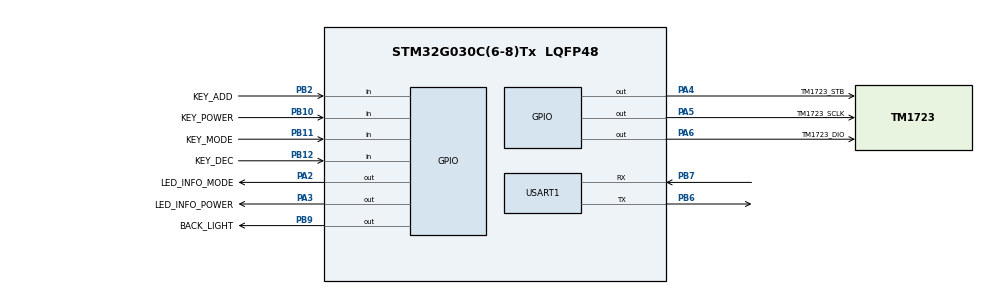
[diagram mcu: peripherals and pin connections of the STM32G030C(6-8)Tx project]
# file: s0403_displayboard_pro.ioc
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Dma.Request0=USART1_RX
Dma.Request1=USART1_TX
Dma.USART1_RX.0.Direction=DMA_PERIPH_TO_MEMORY
Dma.USART1_RX.0.EventEnable=DISABLE
Dma.USART1_RX.0.Instance=DMA1_Channel1
Dma.USART1_RX.0.MemDataAlignment=DMA_MDATAALIGN_BYTE
Dma.USART1_RX.0.MemInc=DMA_MINC_ENABLE
Dma.USART1_RX.0.Mode=DMA_NORMAL
Dma.USART1_RX.0.PeriphDataAlignment=DMA_PDATAALIGN_BYTE
Dma.USART1_RX.0.PeriphInc=DMA_PINC_DISABLE
Dma.USART1_RX.0.Polarity=HAL_DMAMUX_REQ_GEN_RISING
Dma.USART1_RX.0.Priority=DMA_PRIORITY_LOW
Dma.USART1_RX.0.RequestNumber=1
Dma.USART1_RX.0.SignalID=NONE
Dma.USART1_RX.0.SyncEnable=DISABLE
Dma.USART1_RX.0.SyncPolarity=HAL_DMAMUX_SYNC_NO_EVENT
Dma.USART1_RX.0.SyncRequestNumber=1
Dma.USART1_RX.0.SyncSignalID=NONE
Dma.USART1_TX.1.Direction=DMA_MEMORY_TO_PERIPH
Dma.USART1_TX.1.EventEnable=DISABLE
Dma.USART1_TX.1.Instance=DMA1_Channel2
Dma.USART1_TX.1.MemDataAlignment=DMA_MDATAALIGN_BYTE
Dma.USART1_TX.1.MemInc=DMA_MINC_ENABLE
Dma.USART1_TX.1.Mode=DMA_NORMAL
Dma.USART1_TX.1.PeriphDataAlignment=DMA_PDATAALIGN_BYTE
Dma.USART1_TX.1.PeriphInc=DMA_PINC_DISABLE
Dma.USART1_TX.1.Polarity=HAL_DMAMUX_REQ_GEN_RISING
Dma.USART1_TX.1.Priority=DMA_PRIORITY_LOW
Dma.USART1_TX.1.RequestNumber=1
Dma.USART1_TX.1.SignalID=NONE
Dma.USART1_TX.1.SyncEnable=DISABLE
Dma.USART1_TX.1.SyncPolarity=HAL_DMAMUX_SYNC_NO_EVENT
Dma.USART1_TX.1.SyncRequestNumber=1
Dma.USART1_TX.1.SyncSignalID=NONE
Mcu.Family=STM32G0
Mcu.Name=STM32G030C(6-8)Tx
Mcu.Package=LQFP48
NVIC.DMA1_Channel1_IRQn=true\:0\:0\:false\:false\:true\:false\:false\:true\:true
NVIC.DMA1_Channel2_3_IRQn=true\:0\:0\:false\:false\:true\:false\:false\:true\:true
NVIC.TIM16_IRQn=true\:0\:0\:false\:false\:true\:false\:true\:true\:true
NVIC.TIM17_IRQn=true\:3\:0\:false\:false\:true\:false\:false\:true\:true
NVIC.TimeBase=TIM17_IRQn
NVIC.TimeBaseIP=TIM17
NVIC.USART1_IRQn=true\:0\:0\:false\:false\:true\:false\:true\:true\:true
PA13.Mode=Serial_Wire
PA13.Signal=SYS_SWDIO
PA14-BOOT0.Mode=Serial_Wire
PA14-BOOT0.Signal=SYS_SWCLK
PA2.GPIO_Label=LED_INFO_MODE
PA2.Signal=GPIO_Output
PA3.GPIO_Label=LED_INFO_POWER
PA3.Signal=GPIO_Output
PA4.GPIO_Label=TM1723_STB
PA4.Signal=GPIO_Output
PA5.GPIO_Label=TM1723_SCLK
PA5.Signal=GPIO_Output
PA6.GPIO_Label=TM1723_DIO
PA6.Signal=GPIO_Output
PB10.GPIO_Label=KEY_POWER
PB10.Signal=GPIO_Input
PB11.GPIO_Label=KEY_MODE
PB11.Signal=GPIO_Input
PB12.GPIO_Label=KEY_DEC
PB12.Signal=GPIO_Input
PB2.GPIO_Label=KEY_ADD
PB2.Signal=GPIO_Input
PB6.Mode=Asynchronous
PB6.Signal=USART1_TX
PB7.Mode=Asynchronous
PB7.Signal=USART1_RX
PB9.GPIO_Label=BACK_LIGHT
PB9.Signal=GPIO_Output
ProjectManager.HeapSize=0x200
ProjectManager.StackSize=0x400
ProjectManager.TargetToolchain=MDK-ARM V5.32
RCC.ADCFreq_Value=64000000
RCC.AHBFreq_Value=64000000
RCC.CortexFreq_Value=64000000
RCC.EXTERNAL_CLOCK_VALUE=12288000
RCC.HCLKFreq_Value=64000000
RCC.HSE_VALUE=8000000
RCC.HSI_VALUE=16000000
RCC.LSE_VALUE=32768
RCC.SYSCLKFreq_VALUE=64000000
RCC.SYSCLKSource=RCC_SYSCLKSOURCE_PLLCLK
RCC.VCOOutputFreq_Value=128000000
STMicroelectronics.X-CUBE-AZRTOS-G0.1.1.0.ThreadXCcRTOSJjThreadXJjCore=true
STMicroelectronics.X-CUBE-AZRTOS-G0.1.1.0_IsAnAzureRtosMw=true
USART1.VirtualMode-Asynchronous=VM_ASYNC
VP_STMicroelectronics.X-CUBE-AZRTOS-G0_VS_RTOSJjThreadX_6.1.10_1.1.0.Mode=RTOSJjThreadX
VP_SYS_VS_tim17.Mode=TIM17
VP_TIM16_VS_ClockSourceINT.Mode=Enable_Timer
board=custom

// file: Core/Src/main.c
/* USER CODE BEGIN Header */
/**
  ******************************************************************************
  * @file           : main.c
  * @brief          : Main program body
  ******************************************************************************
  * @attention
  *
  * version : 2.4 . be used to LL lib .
  *           data:2025.09.22
  *
  * data:2026.02.27
  * modify 0x6C order send to mainboard sync times is local don't beijing time.
  * data:2026-06-05 be used responsed speed .
  *
  *
  ******************************************************************************
  */
/* USER CODE END Header */
#include "app_threadx.h"
#include "main.h"
#include "dma.h"
#include "tim.h"
#include "usart.h"
#include "gpio.h"

/* USER CODE BEGIN Includes */
#include "bsp.h"
/* USER CODE END Includes */

void SystemClock_Config(void);

int main(void)
{

  /* MCU Configuration--------------------------------------------------------*/

  /* Reset of all peripherals, Initializes the Flash interface and the Systick. */
  HAL_Init();

  /* Configure the system clock */
  SystemClock_Config();

  /* Initialize all configured peripherals */
  MX_GPIO_Init();
  MX_DMA_Init();
  MX_USART1_UART_Init();
  MX_TIM16_Init();
  /* USER CODE BEGIN 2 */
  bsp_init();

  /* USER CODE END 2 */

  MX_ThreadX_Init();

  /* We should never get here as control is now taken by the scheduler */

  /* Infinite loop */
  while (1)
  {

  }
}

void SystemClock_Config(void)
{
  LL_FLASH_SetLatency(LL_FLASH_LATENCY_2);
  while(LL_FLASH_GetLatency() != LL_FLASH_LATENCY_2)
  {
  }

  /* HSI configuration and activation */
  LL_RCC_HSI_Enable();
  while(LL_RCC_HSI_IsReady() != 1)
  {
  }

  /* Main PLL configuration and activation */
  LL_RCC_PLL_ConfigDomain_SYS(LL_RCC_PLLSOURCE_HSI, LL_RCC_PLLM_DIV_1, 8, LL_RCC_PLLR_DIV_2);
  LL_RCC_PLL_Enable();
  LL_RCC_PLL_EnableDomain_SYS();
  while(LL_RCC_PLL_IsReady() != 1)
  {
  }

  /* Set AHB prescaler*/
  LL_RCC_SetAHBPrescaler(LL_RCC_SYSCLK_DIV_1);

  /* Sysclk activation on the main PLL */
  LL_RCC_SetSysClkSource(LL_RCC_SYS_CLKSOURCE_PLL);
  while(LL_RCC_GetSysClkSource() != LL_RCC_SYS_CLKSOURCE_STATUS_PLL)
  {
  }

  /* Set APB1 prescaler*/
  LL_RCC_SetAPB1Prescaler(LL_RCC_APB1_DIV_1);
  /* Update CMSIS variable (which can be updated also through SystemCoreClockUpdate function) */
  LL_SetSystemCoreClock(64000000);

   /* Update the time base */
  if (HAL_InitTick (TICK_INT_PRIORITY) != HAL_OK)
  {
    Error_Handler();
  }
}

void HAL_TIM_PeriodElapsedCallback(TIM_HandleTypeDef *htim)
{
  if (htim->Instance == TIM17)
  {
    HAL_IncTick();
  }
}

void Error_Handler(void)
{
  __disable_irq();
  while (1)
  {
  }
}
